# Ij7am_cnm_wave521cl_main_0_pri_m_vbusm_w_bw_limiter0_REGS register map
Vendor: Texas Instruments
Peripheral module from a debugger description file (folder J7_AHP).
Registers are 32-bit, read-only, reset 0x0 unless marked. A register's access mark holds for its fields unless they carry their own. Offsets are as the file gives them; lines under a group give offsets from that group; [hi:lo] are bit positions; {n}, {i} and the like mark numbered series; 'fields as' and 'values as' point back to an identical list; <NAME> marks a mode.

## Ij7am_cnm_wave521cl_main_0_pri_m_vbusm_w_bw_limiter0_REGS
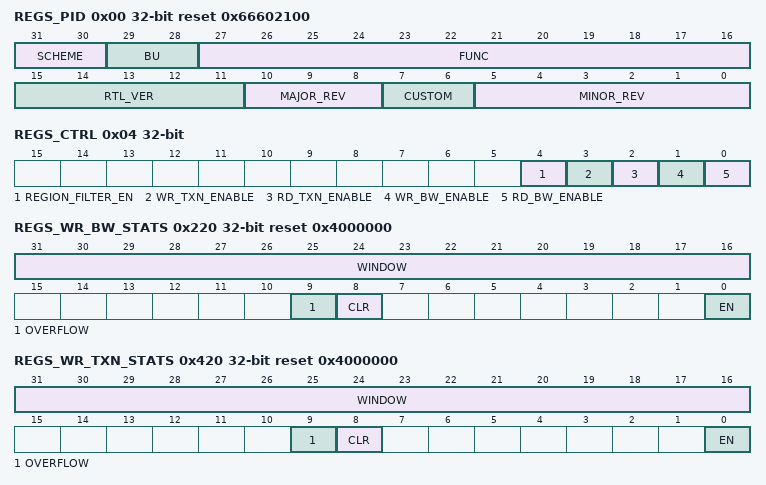
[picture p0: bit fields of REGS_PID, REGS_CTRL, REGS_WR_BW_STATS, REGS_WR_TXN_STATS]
0x00 REGS_PID reset 0x66602100
  [31:30] SCHEME — PID scheme
  [29:28] BU — PID bu identifier
  [27:16] FUNC — PID function identifier
  [15:11] RTL_VER — PID RTL version number
  [10:8] MAJOR_REV — PID Major revision number
  [7:6] CUSTOM — PID custom
  [5:0] MINOR_REV — PID Minor revision number
0x04 REGS_CTRL rw
  [4] REGION_FILTER_EN — Enable the region filter, which will only apply the bandwith and transaction limits to the configured address regions
  [3] WR_TXN_ENABLE — Enable limiting maximum outstanding write transactions
  [2] RD_TXN_ENABLE — Enable limiting maximum outstanding read transactions
  [1] WR_BW_ENABLE — Enable write bandwidth limiting
  [0] RD_BW_ENABLE — Enable read bandwidth limiting
0x200 REGS_WR_BW_CIR rw
  [31:0] CIR — Committed Information Rate
0x204 REGS_WR_BW_PIR rw
  [31:0] PIR — Peak Information Rate
0x208 REGS_WR_BW_BURST_OFFSET rw
  [15:0] OFFSET — Burst Offset - the number of bytes before the Committed Information Rate is applied at startup or after a period of inactivity. Peak Information Rate will still apply
0x20C REGS_WR_BW_INFO
  [1:0] COLOR — Write Bandwidth three-color marker output from rategen submodule
0x220 REGS_WR_BW_STATS access per field reset 0x4000000
  [31:16] WINDOW rw — Statistics window size. This cannot be set to 0. If 16'd0 is written, it will be set to the reset value of 16'd1024
  [9] OVERFLOW ro — Statistics overflow error
  [8] CLR wo — Clear statistics data. Resets statistics counters at 0
  [0] EN rw — Enable write bandwidth statistics
0x224 REGS_WR_BW_STATS_THRSHLD rw
  [31:0] THRESHOLD — Write bandwidth stats threshold in bytes. Note that this is total bytes, unlike CIR and PIR. CIR and PIR are based on a rolling window, and the statistics threshold is based on a fixed window. This will still take into account DDR bytes used, so can be compared to CIR and PIR directly if the bandwidths are converted via the equations for CIR and PIR. The threshold bandwidth is programmed here as bytes per window
0x228 REGS_WR_BW_WINDOWS_CNT
  [31:0] VAL — Write bandwidth window count - the number of windows elapsed since statistics collection began
0x22C REGS_WR_BW_CIR_CNT
  [31:0] VAL — The total number of statistics windows in which Write Commit Information Rate occurred. Note that if PIR is set to a lower value than CIR or if the burst offset feature is used, this will also count times that PIR is reached.
0x230 REGS_WR_BW_PIR_CNT
  [31:0] VAL — The total number of statistics windows in which Write Peak Information Rate occurred
0x234 REGS_WR_BW_THRSHLD_CNT
  [31:0] VAL — The total number of statistics windows in which Write bytes transferred exceeded the statistics threshold
0x238 REGS_WR_BYTES_MAX
  [31:0] VAL — Max number of bytes in a single window. This number accounts for DDR bandwidth consumed, not simply the accumulation of the packet bytecnt values across a window. The max bandwidth calculation is the total bytes value in this MMR divided by the windows size in WR_BW_STATS.window and multiplied with the interface frequency: WR_BYTES_MAX * FREQ / WR_BW_STATS.window
0x400 REGS_WR_TXN rw reset 0x40
  [15:0] LIMIT — The maximum number of outstanding write transactions allowed. NOTE: This cannot be programmed to a zero. If a zero is written, it will default to the reset value of 16'd64, as a limit of zero outstanding transactions would hang the interface.
0x40C REGS_WR_TXN_INFO
  [6:0] OCC — Write transaction scoreboard occupancy
0x420 REGS_WR_TXN_STATS access per field reset 0x4000000
  [31:16] WINDOW rw — Statistics window size. This cannot be set to 0. If 16'd0 is written, it will be set to the reset value of 16'd1024
  [9] OVERFLOW ro — Statistics overflow error
  [8] CLR wo — Clear statistics data. Resets statistics counters at 0
  [0] EN rw — Enable write transaction statistics
0x424 REGS_WR_TXN_STATS_THRSHLD rw
  [15:0] THRESHOLD — Write transaction statistics threshold. The threshold can be set to any value, though it will saturate at the outstanding transaction limit if it is set to a value greater than the programmed outstanding write transaction limit
0x428 REGS_WR_TXN_WINDOWS_CNT
  [31:0] VAL — Write transaction window count - the number of windows elapsed since statistics collection began
0x42C REGS_WR_TXN_LMT_CNT
  [31:0] VAL — The number of statistics windows in which the outstanding write transaction limit was reached
0x430 REGS_WR_TXN_THRSHLD_CNT
  [31:0] VAL — The number of statistics windows in which the number of outstanding write transactions was greater than or equal to the threshold in WR_TXN_STATS_THRSHLD
0x434 REGS_WR_TXN_LIMIT_TOTAL
  [31:0] VAL — The total number of cycles with the write transactions outstanding at the programmed limit since statistics collection began
0x438 REGS_WR_TXN_THRSHLD_TOTAL
  [31:0] VAL — The total number of cycles with write transactions outstanding greater than or equal to the statistics threshold in WR_TXN_STATS_THRSHLD since statistics collection began
0x43C REGS_WR_TXN_MAX
  [15:0] VAL — The maximum outstanding write transactions at any point in time, regardless of the programmed limit
